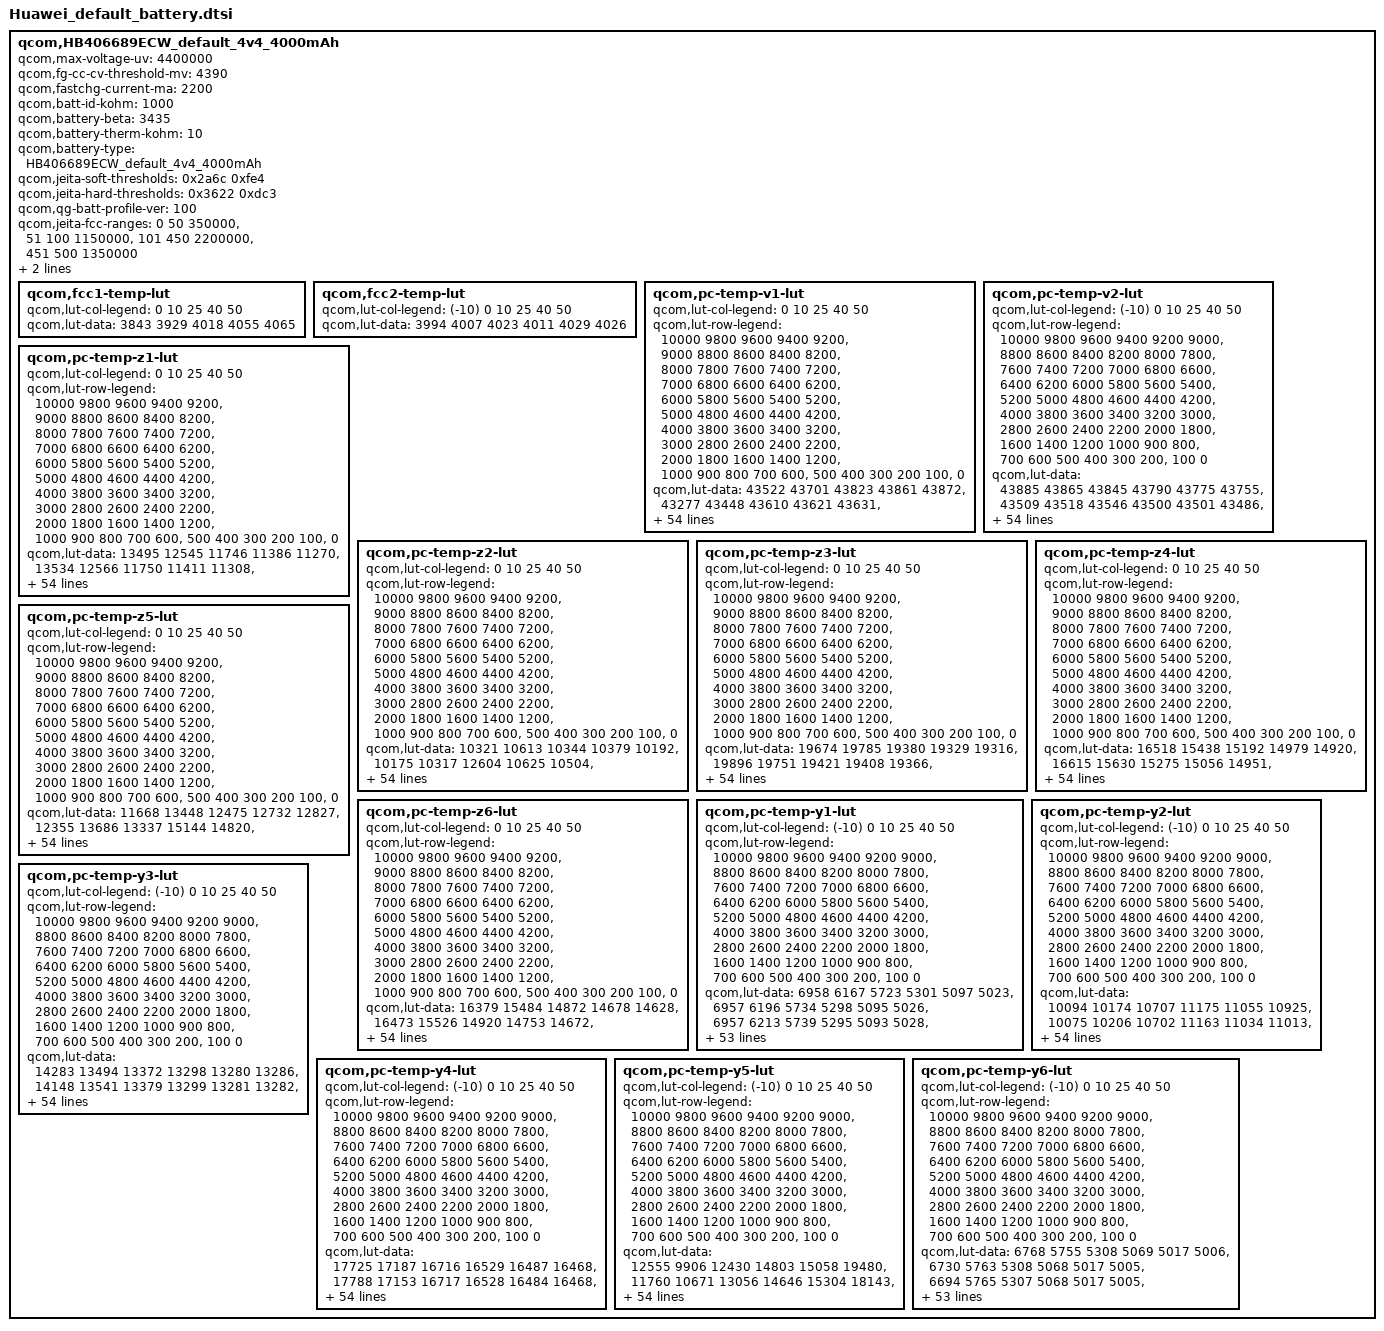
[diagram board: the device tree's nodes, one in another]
/* Copyright (c) 2018, The Linux Foundation. All rights reserved.
 *
 * This program is free software; you can redistribute it and/or modify
 * it under the terms of the GNU General Public License version 2 and
 * only version 2 as published by the Free Software Foundation.
 *
 * This program is distributed in the hope that it will be useful,
 * but WITHOUT ANY WARRANTY; without even the implied warranty of
 * MERCHANTABILITY or FITNESS FOR A PARTICULAR PURPOSE.  See the
 * GNU General Public License for more details.
 */

qcom,HB406689ECW_default_4v4_4000mAh {
	/* 3460679_Huawei_Bangkok_desay_4000mAh_averaged_MasterSlave_May29th2018 */
	qcom,max-voltage-uv = <4400000>;
	qcom,fg-cc-cv-threshold-mv = <4390>;
	qcom,fastchg-current-ma = <2200>;
	qcom,batt-id-kohm = <1000>;
	qcom,battery-beta = <3435>;
	qcom,battery-therm-kohm = <10>;
	qcom,battery-type = "HB406689ECW_default_4v4_4000mAh";
	qcom,jeita-soft-thresholds = <0x2a6c 0xfe4>;
	qcom,jeita-hard-thresholds = <0x3622 0xdc3>;
	qcom,qg-batt-profile-ver = <100>;

	qcom,jeita-fcc-ranges = <0   50  350000>,
				<51  100  1150000>,
				<101  450  2200000>,
				<451  500  1350000>;
	qcom,jeita-fv-ranges = <0   450  4400000>,
				<451 500  4100000>;

	qcom,fcc1-temp-lut {
		qcom,lut-col-legend = <0 10 25 40 50>;
		qcom,lut-data = <3843 3929 4018 4055 4065>;
	};

	qcom,fcc2-temp-lut {
		qcom,lut-col-legend = <(-10) 0 10 25 40 50>;
		qcom,lut-data = <3994 4007 4023 4011 4029 4026>;
	};

	qcom,pc-temp-v1-lut {
		qcom,lut-col-legend = <0 10 25 40 50>;
		qcom,lut-row-legend = <10000 9800 9600 9400 9200>,
			<9000 8800 8600 8400 8200>,
			<8000 7800 7600 7400 7200>,
			<7000 6800 6600 6400 6200>,
			<6000 5800 5600 5400 5200>,
			<5000 4800 4600 4400 4200>,
			<4000 3800 3600 3400 3200>,
			<3000 2800 2600 2400 2200>,
			<2000 1800 1600 1400 1200>,
			<1000 900 800 700 600>,
			<500 400 300 200 100>,
			<0>;
		qcom,lut-data = <43522 43701 43823 43861 43872>,
			<43277 43448 43610 43621 43631>,
			<43036 43204 43364 43394 43405>,
			<42798 42966 43119 43168 43181>,
			<42564 42734 42884 42935 42951>,
			<42334 42501 42651 42698 42719>,
			<42110 42271 42418 42465 42486>,
			<41893 42047 42185 42232 42254>,
			<41682 41827 41956 42002 42024>,
			<41480 41611 41729 41775 41794>,
			<41289 41403 41506 41550 41566>,
			<41095 41201 41292 41330 41344>,
			<40889 41002 41085 41112 41128>,
			<40679 40807 40880 40901 40919>,
			<40463 40612 40675 40697 40713>,
			<40233 40404 40474 40500 40514>,
			<40024 40182 40277 40307 40323>,
			<39861 39990 40088 40120 40142>,
			<39724 39846 39920 39943 39968>,
			<39597 39717 39782 39792 39810>,
			<39481 39577 39634 39641 39653>,
			<39368 39432 39432 39438 39455>,
			<39240 39269 39195 39169 39195>,
			<39099 39039 38987 38951 38977>,
			<38960 38793 38797 38811 38834>,
			<38826 38652 38647 38697 38718>,
			<38699 38569 38560 38597 38612>,
			<38602 38505 38496 38509 38515>,
			<38526 38450 38431 38424 38423>,
			<38462 38404 38365 38336 38329>,
			<38410 38358 38302 38255 38242>,
			<38364 38311 38241 38187 38170>,
			<38324 38267 38184 38128 38108>,
			<38287 38226 38131 38071 38048>,
			<38253 38189 38085 38018 37989>,
			<38217 38150 38041 37966 37931>,
			<38182 38115 38000 37917 37873>,
			<38140 38075 37959 37871 37815>,
			<38077 38010 37900 37808 37743>,
			<37995 37913 37810 37719 37652>,
			<37895 37804 37703 37613 37546>,
			<37763 37679 37583 37493 37428>,
			<37616 37538 37447 37354 37292>,
			<37453 37375 37286 37196 37131>,
			<37324 37237 37147 37061 36999>,
			<37231 37156 37064 36981 36923>,
			<37207 37131 37040 36961 36904>,
			<37185 37111 37026 36949 36889>,
			<37159 37094 37007 36927 36866>,
			<37093 37030 36944 36838 36760>,
			<36816 36734 36664 36519 36429>,
			<36349 36270 36215 36058 35964>,
			<35748 35672 35627 35454 35359>,
			<34926 34842 34820 34622 34525>,
			<33595 33521 33557 33301 33198>,
			<30000 30000 30000 30000 30000>;
	};

	qcom,pc-temp-v2-lut {
		qcom,lut-col-legend = <(-10) 0 10 25 40 50>;
		qcom,lut-row-legend = <10000 9800 9600 9400 9200 9000>,
			<8800 8600 8400 8200 8000 7800>,
			<7600 7400 7200 7000 6800 6600>,
			<6400 6200 6000 5800 5600 5400>,
			<5200 5000 4800 4600 4400 4200>,
			<4000 3800 3600 3400 3200 3000>,
			<2800 2600 2400 2200 2000 1800>,
			<1600 1400 1200 1000 900 800>,
			<700 600 500 400 300 200>,
			<100 0>;
		qcom,lut-data = <43885 43865 43845 43790 43775 43755>,
			<43509 43518 43546 43500 43501 43486>,
			<43165 43201 43265 43228 43238 43228>,
			<42856 42919 43003 42973 42990 42982>,
			<42573 42671 42761 42737 42756 42748>,
			<42326 42429 42523 42506 42524 42516>,
			<42128 42183 42285 42273 42291 42284>,
			<41946 41940 42051 42042 42059 42054>,
			<41713 41705 41823 41815 41831 41827>,
			<41406 41472 41600 41590 41605 41601>,
			<41177 41258 41383 41369 41383 41379>,
			<41086 41078 41173 41154 41163 41161>,
			<41016 40906 40968 40943 40947 40947>,
			<40824 40711 40767 40739 40744 40741>,
			<40321 40492 40569 40540 40548 40541>,
			<39874 40256 40369 40344 40355 40348>,
			<39653 39978 40165 40140 40156 40161>,
			<39482 39695 39959 39944 39964 39981>,
			<39307 39488 39748 39780 39796 39812>,
			<39132 39329 39531 39645 39649 39655>,
			<38963 39172 39323 39488 39480 39481>,
			<38792 38994 39121 39253 39254 39258>,
			<38629 38819 38932 38999 39022 39031>,
			<38498 38669 38771 38811 38840 38849>,
			<38387 38540 38629 38660 38683 38692>,
			<38295 38415 38503 38532 38550 38558>,
			<38220 38276 38391 38421 38437 38445>,
			<38156 38148 38290 38322 38339 38345>,
			<38095 38069 38197 38231 38248 38251>,
			<38035 38014 38110 38147 38165 38164>,
			<37979 37967 38029 38072 38090 38087>,
			<37923 37921 37949 38001 38021 38017>,
			<37869 37879 37879 37937 37956 37951>,
			<37813 37836 37828 37875 37888 37884>,
			<37759 37795 37789 37818 37821 37818>,
			<37702 37750 37750 37761 37745 37737>,
			<37637 37700 37712 37701 37653 37625>,
			<37569 37644 37671 37638 37558 37507>,
			<37499 37583 37618 37568 37474 37415>,
			<37428 37516 37550 37490 37395 37334>,
			<37356 37437 37467 37403 37307 37245>,
			<37283 37334 37357 37301 37208 37146>,
			<37209 37215 37229 37181 37089 37029>,
			<37137 37079 37078 37032 36943 36884>,
			<37053 36963 36948 36918 36846 36788>,
			<36955 36873 36887 36876 36816 36764>,
			<36900 36841 36866 36861 36802 36747>,
			<36837 36806 36844 36842 36780 36728>,
			<36764 36752 36804 36805 36733 36679>,
			<36634 36646 36684 36689 36560 36492>,
			<36391 36373 36355 36361 36160 36083>,
			<35975 35891 35825 35848 35613 35540>,
			<35369 35221 35119 35181 34899 34822>,
			<34492 34264 34117 34271 33895 33844>,
			<33004 32661 32620 32827 32381 32322>,
			<28729 27708 27041 28388 27084 27118>;
	};

	qcom,pc-temp-z1-lut {
		qcom,lut-col-legend = <0 10 25 40 50>;
		qcom,lut-row-legend = <10000 9800 9600 9400 9200>,
			<9000 8800 8600 8400 8200>,
			<8000 7800 7600 7400 7200>,
			<7000 6800 6600 6400 6200>,
			<6000 5800 5600 5400 5200>,
			<5000 4800 4600 4400 4200>,
			<4000 3800 3600 3400 3200>,
			<3000 2800 2600 2400 2200>,
			<2000 1800 1600 1400 1200>,
			<1000 900 800 700 600>,
			<500 400 300 200 100>,
			<0>;
		qcom,lut-data = <13495 12545 11746 11386 11270>,
			<13534 12566 11750 11411 11308>,
			<13548 12567 11761 11415 11311>,
			<13557 12558 11761 11415 11311>,
			<13564 12550 11754 11413 11311>,
			<13570 12549 11745 11409 11310>,
			<13577 12546 11736 11406 11309>,
			<13588 12545 11726 11404 11309>,
			<13595 12544 11720 11401 11308>,
			<13588 12541 11717 11400 11307>,
			<13560 12537 11714 11399 11304>,
			<13538 12531 11714 11398 11303>,
			<13527 12523 11713 11398 11303>,
			<13515 12493 11712 11397 11304>,
			<13506 12459 11708 11395 11303>,
			<13500 12454 11704 11393 11302>,
			<13493 12454 11702 11393 11302>,
			<13479 12454 11699 11394 11302>,
			<13459 12446 11699 11394 11303>,
			<13436 12436 11703 11396 11305>,
			<13408 12436 11708 11398 11306>,
			<13384 12450 11712 11399 11308>,
			<13376 12462 11716 11401 11309>,
			<13381 12469 11720 11403 11311>,
			<13385 12476 11724 11405 11312>,
			<13388 12478 11729 11408 11315>,
			<13392 12479 11733 11411 11317>,
			<13389 12480 11736 11415 11321>,
			<13371 12478 11741 11419 11324>,
			<13355 12476 11747 11424 11327>,
			<13358 12476 11753 11430 11331>,
			<13368 12482 11759 11435 11334>,
			<13372 12489 11763 11440 11338>,
			<13380 12492 11767 11443 11341>,
			<13393 12495 11770 11445 11345>,
			<13407 12498 11773 11447 11347>,
			<13430 12502 11780 11449 11350>,
			<13442 12508 11788 11452 11352>,
			<13434 12512 11795 11455 11355>,
			<13421 12517 11800 11460 11358>,
			<13418 12523 11805 11465 11361>,
			<13423 12541 11811 11470 11363>,
			<13426 12555 11818 11474 11365>,
			<13427 12567 11824 11477 11368>,
			<13441 12562 11832 11482 11372>,
			<13401 12555 11839 11486 11375>,
			<13400 12546 11837 11487 11375>,
			<13408 12521 11841 11487 11376>,
			<13404 12544 11847 11489 11377>,
			<13420 12543 11842 11493 11382>,
			<13414 12563 11853 11499 11385>,
			<13430 12573 11867 11505 11390>,
			<13442 12593 11878 11514 11398>,
			<13456 12600 11897 11527 11409>,
			<13456 12600 11897 11527 11409>,
			<13456 12600 11897 11527 11409>;
	};

	qcom,pc-temp-z2-lut {
		qcom,lut-col-legend = <0 10 25 40 50>;
		qcom,lut-row-legend = <10000 9800 9600 9400 9200>,
			<9000 8800 8600 8400 8200>,
			<8000 7800 7600 7400 7200>,
			<7000 6800 6600 6400 6200>,
			<6000 5800 5600 5400 5200>,
			<5000 4800 4600 4400 4200>,
			<4000 3800 3600 3400 3200>,
			<3000 2800 2600 2400 2200>,
			<2000 1800 1600 1400 1200>,
			<1000 900 800 700 600>,
			<500 400 300 200 100>,
			<0>;
		qcom,lut-data = <10321 10613 10344 10379 10192>,
			<10175 10317 12604 10625 10504>,
			<10148 10212 11188 11027 10977>,
			<10133 10197 10443 11277 11321>,
			<10120 10188 10422 11061 11296>,
			<10110 10176 10403 10642 11169>,
			<10106 10165 10386 10557 11007>,
			<10111 10158 10370 10722 10731>,
			<10117 10155 10366 10848 10540>,
			<10119 10156 10384 10860 10537>,
			<10128 10160 10408 10872 10542>,
			<10135 10170 10422 10892 10576>,
			<10136 10184 10434 10931 10766>,
			<10136 10210 10463 10953 10920>,
			<10130 10240 10588 10938 10965>,
			<10082 10263 10682 10898 11000>,
			<10040 10284 10718 10812 10944>,
			<10057 10304 10807 10599 10581>,
			<10103 10326 10810 10487 10346>,
			<10121 10343 10635 10502 10357>,
			<10082 10345 10488 10537 10389>,
			<10037 10336 10515 10594 10474>,
			<10053 10328 10583 10712 10719>,
			<10134 10318 10597 10765 10859>,
			<10189 10309 10543 10600 10677>,
			<10201 10308 10496 10397 10420>,
			<10211 10317 10493 10408 10402>,
			<10221 10327 10494 10529 10489>,
			<10228 10333 10505 10625 10553>,
			<10237 10339 10567 10696 10585>,
			<10249 10347 10616 10744 10605>,
			<10263 10357 10592 10705 10578>,
			<10278 10367 10544 10581 10482>,
			<10295 10372 10527 10533 10441>,
			<10312 10375 10523 10561 10482>,
			<10332 10379 10521 10605 10544>,
			<10355 10386 10529 10650 10603>,
			<10379 10394 10549 10703 10671>,
			<10405 10406 10573 10741 10705>,
			<10434 10425 10610 10770 10705>,
			<10467 10445 10642 10789 10697>,
			<10508 10464 10656 10798 10708>,
			<10570 10495 10669 10802 10728>,
			<10686 10570 10695 10784 10721>,
			<10898 10889 10825 10799 10670>,
			<11114 11109 10913 10813 10594>,
			<10449 11192 10894 10712 10552>,
			<10384 11229 10922 10683 10571>,
			<10369 11234 10893 10697 10605>,
			<10369 11257 10999 10878 10656>,
			<10399 11426 11258 10831 10488>,
			<10232 11396 11217 10758 10378>,
			<10091 10856 11210 10661 10346>,
			<9949 10726 11167 10611 10274>,
			<9949 10726 11167 10611 10274>,
			<9949 10726 11167 10611 10274>;
	};

	qcom,pc-temp-z3-lut {
		qcom,lut-col-legend = <0 10 25 40 50>;
		qcom,lut-row-legend = <10000 9800 9600 9400 9200>,
			<9000 8800 8600 8400 8200>,
			<8000 7800 7600 7400 7200>,
			<7000 6800 6600 6400 6200>,
			<6000 5800 5600 5400 5200>,
			<5000 4800 4600 4400 4200>,
			<4000 3800 3600 3400 3200>,
			<3000 2800 2600 2400 2200>,
			<2000 1800 1600 1400 1200>,
			<1000 900 800 700 600>,
			<500 400 300 200 100>,
			<0>;
		qcom,lut-data = <19674 19785 19380 19329 19316>,
			<19896 19751 19421 19408 19366>,
			<19982 19756 19514 19439 19394>,
			<20030 19782 19557 19455 19416>,
			<20058 19800 19561 19460 19432>,
			<20078 19801 19563 19463 19444>,
			<20084 19801 19563 19468 19446>,
			<20072 19800 19563 19482 19431>,
			<20057 19792 19561 19491 19415>,
			<20053 19781 19551 19480 19411>,
			<20039 19779 19540 19460 19409>,
			<20033 19778 19528 19452 19408>,
			<20040 19775 19516 19449 19407>,
			<20050 19756 19512 19446 19405>,
			<20075 19731 19523 19440 19403>,
			<20169 19722 19532 19430 19401>,
			<20246 19717 19533 19419 19394>,
			<20233 19713 19534 19404 19372>,
			<20182 19698 19528 19392 19355>,
			<20129 19681 19499 19385 19351>,
			<19965 19680 19477 19380 19348>,
			<19800 19695 19489 19386 19352>,
			<19832 19714 19518 19411 19373>,
			<20018 19741 19526 19425 19385>,
			<20126 19770 19517 19406 19366>,
			<20121 19775 19505 19379 19338>,
			<20115 19768 19489 19369 19335>,
			<20107 19758 19473 19362 19339>,
			<20089 19747 19469 19361 19345>,
			<20068 19734 19474 19395 19375>,
			<20048 19725 19480 19433 19410>,
			<20026 19720 19492 19434 19409>,
			<20002 19716 19509 19427 19395>,
			<19975 19712 19513 19421 19384>,
			<19947 19708 19508 19415 19378>,
			<19924 19704 19503 19409 19374>,
			<19903 19699 19498 19405 19372>,
			<19884 19694 19493 19401 19370>,
			<19866 19690 19488 19396 19368>,
			<19848 19686 19481 19390 19367>,
			<19824 19679 19476 19385 19366>,
			<19787 19667 19472 19386 19365>,
			<19741 19648 19468 19388 19364>,
			<19678 19615 19458 19382 19365>,
			<19435 19529 19433 19371 19359>,
			<19404 19464 19409 19360 19343>,
			<19346 19444 19411 19353 19335>,
			<19339 19431 19396 19341 19334>,
			<19337 19367 19402 19338 19326>,
			<19333 19372 19384 19329 19332>,
			<19340 19412 19349 19331 19341>,
			<19342 19399 19334 19329 19349>,
			<19345 19332 19334 19331 19348>,
			<19352 19331 19333 19335 19355>,
			<19352 19331 19333 19335 19355>,
			<19352 19331 19333 19335 19355>;
	};

	qcom,pc-temp-z4-lut {
		qcom,lut-col-legend = <0 10 25 40 50>;
		qcom,lut-row-legend = <10000 9800 9600 9400 9200>,
			<9000 8800 8600 8400 8200>,
			<8000 7800 7600 7400 7200>,
			<7000 6800 6600 6400 6200>,
			<6000 5800 5600 5400 5200>,
			<5000 4800 4600 4400 4200>,
			<4000 3800 3600 3400 3200>,
			<3000 2800 2600 2400 2200>,
			<2000 1800 1600 1400 1200>,
			<1000 900 800 700 600>,
			<500 400 300 200 100>,
			<0>;
		qcom,lut-data = <16518 15438 15192 14979 14920>,
			<16615 15630 15275 15056 14951>,
			<16383 15661 15213 15009 14925>,
			<16107 15526 15149 14952 14883>,
			<15930 15358 15086 14922 14848>,
			<15781 15261 15026 14896 14812>,
			<15675 15184 14978 14863 14794>,
			<15597 15125 14936 14811 14783>,
			<15533 15079 14898 14773 14775>,
			<15480 15040 14859 14763 14767>,
			<15428 15001 14829 14757 14756>,
			<15381 14962 14816 14748 14746>,
			<15340 14931 14807 14735 14729>,
			<15301 14905 14794 14724 14714>,
			<15247 14886 14763 14716 14704>,
			<15152 14885 14740 14710 14692>,
			<15082 14892 14725 14707 14689>,
			<15076 14895 14699 14713 14702>,
			<15075 14883 14691 14714 14710>,
			<15080 14861 14700 14709 14704>,
			<15212 14839 14715 14703 14697>,
			<15351 14810 14737 14715 14705>,
			<15286 14794 14771 14773 14758>,
			<15032 14834 14811 14825 14809>,
			<14884 14902 14870 14859 14842>,
			<14888 14918 14910 14883 14866>,
			<14896 14914 14908 14883 14865>,
			<14899 14909 14901 14873 14846>,
			<14901 14899 14890 14858 14820>,
			<14903 14885 14866 14806 14769>,
			<14901 14871 14837 14750 14717>,
			<14896 14855 14804 14729 14705>,
			<14894 14840 14769 14717 14700>,
			<14894 14827 14752 14712 14699>,
			<14894 14815 14743 14711 14699>,
			<14893 14805 14739 14711 14699>,
			<14892 14796 14738 14712 14701>,
			<14891 14790 14738 14716 14707>,
			<14886 14790 14741 14722 14713>,
			<14880 14791 14757 14736 14721>,
			<14882 14791 14769 14747 14727>,
			<14898 14788 14763 14741 14722>,
			<14906 14786 14755 14732 14715>,
			<14912 14786 14755 14737 14716>,
			<14971 14769 14740 14728 14710>,
			<14964 14776 14715 14703 14694>,
			<15025 14789 14701 14695 14688>,
			<15028 14795 14698 14686 14665>,
			<15022 14863 14682 14673 14655>,
			<15014 14853 14707 14694 14663>,
			<15020 14820 14773 14725 14686>,
			<15031 14843 14797 14734 14683>,
			<15033 14926 14802 14735 14685>,
			<15042 14931 14805 14734 14681>,
			<15042 14931 14805 14734 14681>,
			<15042 14931 14805 14734 14681>;
	};

	qcom,pc-temp-z5-lut {
		qcom,lut-col-legend = <0 10 25 40 50>;
		qcom,lut-row-legend = <10000 9800 9600 9400 9200>,
			<9000 8800 8600 8400 8200>,
			<8000 7800 7600 7400 7200>,
			<7000 6800 6600 6400 6200>,
			<6000 5800 5600 5400 5200>,
			<5000 4800 4600 4400 4200>,
			<4000 3800 3600 3400 3200>,
			<3000 2800 2600 2400 2200>,
			<2000 1800 1600 1400 1200>,
			<1000 900 800 700 600>,
			<500 400 300 200 100>,
			<0>;
		qcom,lut-data = <11668 13448 12475 12732 12827>,
			<12355 13686 13337 15144 14820>,
			<12721 13974 14957 15978 15900>,
			<12991 14364 15811 16490 16904>,
			<13248 14748 15968 16843 18033>,
			<13471 15044 16104 17122 19189>,
			<13569 15320 16387 17851 19506>,
			<13563 15522 16805 20101 19021>,
			<13540 15694 17312 21611 18589>,
			<13560 15903 18152 21500 18721>,
			<13631 16316 18805 21231 19172>,
			<13748 17118 18865 21377 19721>,
			<13887 17648 18874 22726 20918>,
			<14078 17848 19264 23638 22272>,
			<14727 17988 22131 23546 23949>,
			<17516 18115 24464 23309 25648>,
			<19814 18244 25343 22634 25259>,
			<19600 18316 27250 20797 20971>,
			<18682 18241 27476 20055 18190>,
			<17735 18169 25523 20552 18468>,
			<16497 18796 23989 21401 19281>,
			<15915 21902 31103 25024 21645>,
			<18125 26288 46456 35915 29252>,
			<24328 34430 50268 41507 33746>,
			<29948 44043 41943 33168 27410>,
			<34073 45507 32490 21713 18116>,
			<37461 39936 26808 18119 15850>,
			<37988 33913 22307 16340 15152>,
			<36271 30276 20783 15900 15020>,
			<34149 27365 20270 18871 19213>,
			<32416 26288 20059 22816 24274>,
			<30340 25930 21815 24699 24761>,
			<28467 25816 25663 26099 24611>,
			<26479 26037 28350 27587 24626>,
			<24635 26461 30494 29712 26408>,
			<23473 26744 31615 31204 28256>,
			<22536 26903 31509 30936 28210>,
			<21984 27133 31144 29770 27626>,
			<21945 27767 30327 28068 26725>,
			<22068 28872 27648 24384 24280>,
			<21755 29296 25286 21584 21954>,
			<20137 28032 24479 21443 21188>,
			<19100 26156 23820 21414 20746>,
			<18197 23984 22255 19805 20487>,
			<14684 22687 22196 19354 19805>,
			<14206 19162 21838 19372 18432>,
			<12866 17306 22551 18789 17403>,
			<12708 16606 20061 17583 18897>,
			<12700 14133 21461 18210 19633>,
			<12777 14542 18318 16095 18814>,
			<12932 15632 14408 14352 16320>,
			<12773 14794 13498 13842 16625>,
			<12696 12781 13272 13698 15976>,
			<12590 12642 13084 13610 16263>,
			<12590 12642 13084 13610 16263>,
			<12590 12642 13084 13610 16263>;
	};

	qcom,pc-temp-z6-lut {
		qcom,lut-col-legend = <0 10 25 40 50>;
		qcom,lut-row-legend = <10000 9800 9600 9400 9200>,
			<9000 8800 8600 8400 8200>,
			<8000 7800 7600 7400 7200>,
			<7000 6800 6600 6400 6200>,
			<6000 5800 5600 5400 5200>,
			<5000 4800 4600 4400 4200>,
			<4000 3800 3600 3400 3200>,
			<3000 2800 2600 2400 2200>,
			<2000 1800 1600 1400 1200>,
			<1000 900 800 700 600>,
			<500 400 300 200 100>,
			<0>;
		qcom,lut-data = <16379 15484 14872 14678 14628>,
			<16473 15526 14920 14753 14672>,
			<16378 15529 14939 14749 14674>,
			<16259 15468 14946 14741 14673>,
			<16176 15390 14922 14733 14670>,
			<16101 15339 14889 14721 14662>,
			<16039 15297 14866 14708 14652>,
			<15988 15260 14847 14696 14640>,
			<15944 15229 14827 14683 14628>,
			<15904 15202 14804 14670 14621>,
			<15868 15179 14784 14658 14615>,
			<15835 15159 14771 14649 14609>,
			<15803 15138 14761 14642 14602>,
			<15777 15107 14753 14635 14595>,
			<15768 15080 14746 14627 14589>,
			<15767 15074 14740 14619 14582>,
			<15765 15072 14732 14612 14576>,
			<15751 15069 14724 14605 14569>,
			<15719 15055 14715 14599 14563>,
			<15687 15037 14705 14593 14558>,
			<15655 15032 14699 14588 14554>,
			<15626 15031 14711 14597 14560>,
			<15607 15030 14743 14639 14598>,
			<15591 15059 14767 14662 14621>,
			<15582 15107 14787 14663 14622>,
			<15580 15118 14799 14664 14622>,
			<15580 15115 14795 14662 14621>,
			<15577 15110 14784 14655 14615>,
			<15569 15101 14775 14648 14609>,
			<15559 15089 14768 14644 14605>,
			<15549 15079 14761 14640 14600>,
			<15538 15071 14755 14634 14594>,
			<15526 15064 14749 14625 14585>,
			<15513 15058 14744 14620 14580>,
			<15501 15052 14739 14616 14576>,
			<15491 15048 14735 14613 14575>,
			<15484 15044 14733 14612 14575>,
			<15477 15042 14731 14612 14575>,
			<15473 15043 14732 14612 14577>,
			<15469 15044 14737 14615 14579>,
			<15462 15045 14740 14618 14582>,
			<15452 15041 14738 14617 14580>,
			<15437 15035 14733 14614 14577>,
			<15414 15024 14730 14613 14578>,
			<15325 14979 14714 14605 14573>,
			<15305 14952 14692 14589 14558>,
			<15299 14949 14687 14582 14551>,
			<15297 14945 14679 14571 14541>,
			<15295 14941 14675 14564 14531>,
			<15297 14946 14678 14569 14538>,
			<15311 14957 14691 14586 14555>,
			<15324 14964 14696 14590 14560>,
			<15337 14973 14701 14594 14563>,
			<15362 14986 14707 14598 14567>,
			<15362 14986 14707 14598 14567>,
			<15362 14986 14707 14598 14567>;
	};

	qcom,pc-temp-y1-lut {
		qcom,lut-col-legend = <(-10) 0 10 25 40 50>;
		qcom,lut-row-legend = <10000 9800 9600 9400 9200 9000>,
			<8800 8600 8400 8200 8000 7800>,
			<7600 7400 7200 7000 6800 6600>,
			<6400 6200 6000 5800 5600 5400>,
			<5200 5000 4800 4600 4400 4200>,
			<4000 3800 3600 3400 3200 3000>,
			<2800 2600 2400 2200 2000 1800>,
			<1600 1400 1200 1000 900 800>,
			<700 600 500 400 300 200>,
			<100 0>;
		qcom,lut-data = <6958 6167 5723 5301 5097 5023>,
			<6957 6196 5734 5298 5095 5026>,
			<6957 6213 5739 5295 5093 5028>,
			<6957 6221 5741 5292 5091 5028>,
			<6958 6222 5741 5288 5089 5029>,
			<6959 6220 5740 5285 5088 5029>,
			<6961 6207 5735 5281 5087 5028>,
			<6964 6189 5728 5277 5086 5026>,
			<6966 6187 5725 5275 5084 5025>,
			<6974 6195 5721 5274 5083 5024>,
			<6979 6201 5717 5273 5082 5023>,
			<6974 6205 5714 5270 5081 5023>,
			<6967 6207 5713 5267 5080 5022>,
			<6964 6208 5712 5266 5079 5022>,
			<6954 6210 5711 5267 5077 5021>,
			<6947 6212 5709 5267 5076 5020>,
			<6947 6215 5710 5269 5077 5022>,
			<6947 6220 5711 5271 5078 5023>,
			<6947 6219 5711 5272 5078 5023>,
			<6945 6210 5709 5272 5078 5023>,
			<6944 6205 5709 5272 5078 5023>,
			<6944 6216 5707 5274 5079 5024>,
			<6942 6234 5706 5277 5079 5025>,
			<6938 6237 5708 5279 5080 5026>,
			<6925 6234 5712 5281 5082 5027>,
			<6914 6231 5717 5284 5084 5027>,
			<6915 6229 5725 5288 5087 5029>,
			<6917 6228 5733 5292 5091 5030>,
			<6915 6223 5738 5296 5093 5032>,
			<6906 6213 5741 5300 5095 5035>,
			<6898 6207 5743 5305 5096 5037>,
			<6902 6212 5740 5310 5099 5040>,
			<6913 6219 5735 5315 5103 5043>,
			<6915 6218 5736 5320 5107 5046>,
			<6903 6209 5739 5324 5112 5050>,
			<6894 6202 5741 5328 5115 5052>,
			<6896 6199 5744 5332 5117 5052>,
			<6901 6197 5747 5336 5119 5052>,
			<6902 6197 5749 5339 5121 5054>,
			<6896 6201 5755 5343 5123 5056>,
			<6890 6204 5760 5347 5125 5057>,
			<6896 6200 5767 5350 5127 5058>,
			<6902 6194 5771 5354 5129 5059>,
			<6928 6185 5788 5360 5133 5063>,
			<6920 6188 5766 5363 5137 5067>,
			<6929 6236 5782 5372 5138 5066>,
			<6939 6238 5801 5367 5140 5068>,
			<6916 6211 5792 5373 5139 5067>,
			<6945 6220 5767 5372 5137 5067>,
			<6973 6234 5777 5380 5138 5069>,
			<6928 6227 5796 5383 5143 5070>,
			<6963 6218 5781 5389 5148 5074>,
			<6917 6238 5802 5405 5156 5081>,
			<6921 6260 5795 5415 5163 5089>,
			<6921 6260 5795 5415 5163 5089>,
			<6921 6260 5795 5415 5163 5089>;
	};

	qcom,pc-temp-y2-lut {
		qcom,lut-col-legend = <(-10) 0 10 25 40 50>;
		qcom,lut-row-legend = <10000 9800 9600 9400 9200 9000>,
			<8800 8600 8400 8200 8000 7800>,
			<7600 7400 7200 7000 6800 6600>,
			<6400 6200 6000 5800 5600 5400>,
			<5200 5000 4800 4600 4400 4200>,
			<4000 3800 3600 3400 3200 3000>,
			<2800 2600 2400 2200 2000 1800>,
			<1600 1400 1200 1000 900 800>,
			<700 600 500 400 300 200>,
			<100 0>;
		qcom,lut-data = <10094 10174 10707 11175 11055 10925>,
			<10075 10206 10702 11163 11034 11013>,
			<10076 10238 10694 11148 11042 11064>,
			<10091 10265 10685 11132 11064 11086>,
			<10117 10285 10678 11117 11087 11090>,
			<10151 10295 10674 11108 11097 11083>,
			<10195 10292 10674 11101 11102 11041>,
			<10251 10286 10674 11095 11115 10986>,
			<10324 10293 10678 11093 11131 10984>,
			<10432 10324 10693 11092 11151 11017>,
			<10497 10365 10702 11090 11159 11047>,
			<10502 10471 10703 11085 11117 11068>,
			<10501 10600 10704 11079 11063 11082>,
			<10469 10623 10723 11085 11066 11062>,
			<10312 10612 10801 11122 11112 10986>,
			<10211 10607 10857 11164 11160 10948>,
			<10033 10638 10874 11202 11203 11013>,
			<9738 10697 10886 11240 11246 11122>,
			<9671 10758 10902 11268 11295 11212>,
			<9669 10830 10921 11294 11362 11304>,
			<9668 10899 10944 11304 11390 11340>,
			<9667 10979 10979 11264 11351 11320>,
			<9666 11047 11023 11209 11297 11281>,
			<9664 11047 11073 11207 11266 11224>,
			<9663 11002 11133 11243 11241 11137>,
			<9662 10976 11180 11285 11234 11103>,
			<9661 11024 11215 11330 11262 11141>,
			<9661 11094 11239 11374 11304 11199>,
			<9660 11002 11245 11397 11357 11242>,
			<9660 10606 11248 11412 11444 11282>,
			<9660 10371 11252 11427 11498 11333>,
			<9659 10127 11261 11454 11525 11417>,
			<9659 9789 11269 11476 11540 11491>,
			<9659 9704 11257 11477 11545 11518>,
			<9658 9687 11214 11470 11549 11538>,
			<9658 9678 11174 11458 11545 11541>,
			<9658 9674 11145 11429 11470 11469>,
			<9657 9671 11116 11395 11388 11383>,
			<9657 9668 11082 11385 11380 11350>,
			<9657 9666 11046 11388 11396 11330>,
			<9657 9663 11009 11387 11407 11304>,
			<9657 9662 10974 11366 11417 11264>,
			<9656 9660 10923 11334 11399 11256>,
			<9656 9659 10836 11301 11333 11295>,
			<9656 9658 10753 11244 11204 11136>,
			<9656 9658 10713 11240 11260 11041>,
			<9656 9657 10683 11227 11205 10977>,
			<9656 9657 10653 11183 11192 11038>,
			<9656 9656 10626 11160 11145 11048>,
			<9656 9656 10578 11115 11135 11028>,
			<9655 9655 10236 11099 11096 10918>,
			<9655 9654 9979 11029 11045 10870>,
			<9654 9654 9714 10936 10991 10831>,
			<9653 9653 9679 10836 10880 10743>,
			<9653 9653 9679 10836 10880 10743>,
			<9653 9653 9679 10836 10880 10743>;
	};

	qcom,pc-temp-y3-lut {
		qcom,lut-col-legend = <(-10) 0 10 25 40 50>;
		qcom,lut-row-legend = <10000 9800 9600 9400 9200 9000>,
			<8800 8600 8400 8200 8000 7800>,
			<7600 7400 7200 7000 6800 6600>,
			<6400 6200 6000 5800 5600 5400>,
			<5200 5000 4800 4600 4400 4200>,
			<4000 3800 3600 3400 3200 3000>,
			<2800 2600 2400 2200 2000 1800>,
			<1600 1400 1200 1000 900 800>,
			<700 600 500 400 300 200>,
			<100 0>;
		qcom,lut-data = <14283 13494 13372 13298 13280 13286>,
			<14148 13541 13379 13299 13281 13282>,
			<14058 13572 13384 13299 13282 13280>,
			<14003 13591 13388 13300 13283 13279>,
			<13976 13600 13391 13301 13285 13279>,
			<13969 13603 13392 13302 13286 13280>,
			<14003 13590 13391 13303 13287 13281>,
			<14057 13572 13389 13304 13288 13284>,
			<14021 13574 13389 13305 13289 13285>,
			<13767 13601 13390 13304 13289 13286>,
			<13599 13618 13391 13304 13289 13287>,
			<13634 13564 13391 13307 13289 13287>,
			<13691 13484 13392 13312 13289 13288>,
			<13696 13480 13391 13314 13290 13288>,
			<13656 13523 13390 13316 13295 13287>,
			<13618 13550 13390 13316 13298 13287>,
			<13585 13528 13395 13314 13297 13289>,
			<13553 13494 13401 13312 13295 13292>,
			<13545 13477 13400 13313 13295 13293>,
			<13544 13470 13391 13319 13296 13293>,
			<13544 13460 13382 13323 13296 13293>,
			<13545 13435 13372 13319 13293 13289>,
			<13545 13409 13362 13312 13289 13284>,
			<13546 13405 13354 13307 13287 13282>,
			<13547 13407 13347 13303 13286 13280>,
			<13551 13407 13343 13301 13284 13279>,
			<13567 13382 13342 13300 13283 13279>,
			<13593 13347 13342 13299 13283 13279>,
			<13619 13344 13342 13299 13283 13278>,
			<13645 13353 13343 13301 13285 13277>,
			<13673 13363 13342 13303 13286 13277>,
			<13704 13372 13336 13303 13286 13278>,
			<13738 13381 13330 13304 13286 13279>,
			<13774 13393 13331 13304 13287 13281>,
			<13814 13407 13337 13305 13287 13282>,
			<13855 13423 13342 13306 13287 13283>,
			<13894 13437 13346 13306 13286 13281>,
			<13933 13454 13350 13306 13284 13278>,
			<13976 13479 13353 13305 13283 13279>,
			<14026 13517 13356 13303 13283 13280>,
			<14077 13560 13356 13303 13283 13280>,
			<14126 13611 13353 13303 13284 13281>,
			<14176 13670 13352 13303 13284 13281>,
			<14234 13738 13351 13303 13282 13280>,
			<14283 13820 13349 13301 13285 13279>,
			<14177 13777 13348 13305 13288 13286>,
			<14217 13850 13357 13308 13291 13287>,
			<14291 13928 13366 13312 13296 13293>,
			<14368 14012 13379 13322 13302 13296>,
			<14449 14110 13385 13325 13298 13292>,
			<14549 14204 13386 13321 13292 13289>,
			<14675 14343 13405 13322 13295 13292>,
			<14863 14512 13444 13333 13304 13295>,
			<15143 14692 13519 13348 13313 13302>,
			<15143 14692 13519 13348 13313 13302>,
			<15143 14692 13519 13348 13313 13302>;
	};

	qcom,pc-temp-y4-lut {
		qcom,lut-col-legend = <(-10) 0 10 25 40 50>;
		qcom,lut-row-legend = <10000 9800 9600 9400 9200 9000>,
			<8800 8600 8400 8200 8000 7800>,
			<7600 7400 7200 7000 6800 6600>,
			<6400 6200 6000 5800 5600 5400>,
			<5200 5000 4800 4600 4400 4200>,
			<4000 3800 3600 3400 3200 3000>,
			<2800 2600 2400 2200 2000 1800>,
			<1600 1400 1200 1000 900 800>,
			<700 600 500 400 300 200>,
			<100 0>;
		qcom,lut-data = <17725 17187 16716 16529 16487 16468>,
			<17788 17153 16717 16528 16484 16468>,
			<17816 17133 16718 16528 16482 16468>,
			<17816 17122 16720 16528 16481 16469>,
			<17796 17118 16721 16529 16480 16469>,
			<17761 17117 16722 16531 16480 16469>,
			<17612 17129 16723 16533 16482 16469>,
			<17410 17146 16724 16538 16484 16469>,
			<17443 17133 16727 16544 16488 16470>,
			<17829 17057 16733 16556 16495 16473>,
			<18084 17011 16741 16566 16503 16477>,
			<18061 17174 16750 16572 16511 16482>,
			<18005 17414 16762 16577 16521 16488>,
			<17889 17430 16792 16586 16527 16496>,
			<17559 17293 16860 16607 16532 16508>,
			<17335 17161 16894 16629 16538 16518>,
			<17361 17066 16882 16650 16550 16523>,
			<17424 16989 16857 16672 16566 16529>,
			<17412 16961 16821 16694 16588 16542>,
			<17332 16950 16761 16718 16620 16566>,
			<17244 16937 16709 16729 16633 16577>,
			<17158 16918 16669 16663 16596 16556>,
			<17081 16891 16641 16565 16543 16524>,
			<17056 16850 16632 16531 16513 16501>,
			<17047 16783 16627 16515 16488 16481>,
			<17042 16749 16625 16509 16480 16474>,
			<17039 16748 16623 16514 16484 16476>,
			<17038 16749 16621 16521 16490 16479>,
			<17038 16754 16617 16527 16497 16485>,
			<17039 16770 16608 16533 16507 16495>,
			<17041 16781 16604 16541 16517 16506>,
			<17043 16796 16605 16551 16534 16518>,
			<17046 16817 16607 16561 16546 16528>,
			<17047 16833 16610 16566 16547 16533>,
			<17048 16846 16617 16569 16547 16537>,
			<17049 16858 16626 16570 16544 16536>,
			<17053 16873 16641 16563 16520 16512>,
			<17058 16887 16656 16552 16498 16486>,
			<17061 16894 16665 16545 16496 16481>,
			<17066 16901 16671 16540 16495 16479>,
			<17073 16903 16674 16538 16496 16478>,
			<17089 16894 16675 16542 16498 16480>,
			<17114 16880 16675 16545 16498 16480>,
			<17140 16868 16668 16539 16493 16471>,
			<17153 16862 16665 16535 16480 16468>,
			<17060 16846 16660 16534 16493 16472>,
			<17062 16858 16674 16550 16506 16493>,
			<17086 16887 16702 16573 16526 16516>,
			<17107 16932 16737 16594 16550 16540>,
			<17116 16965 16759 16601 16529 16508>,
			<17096 16954 16761 16561 16496 16473>,
			<17068 16926 16761 16556 16495 16476>,
			<17063 16931 16810 16570 16507 16488>,
			<17108 16964 16868 16627 16577 16569>,
			<17108 16964 16868 16627 16577 16569>,
			<17108 16964 16868 16627 16577 16569>;
	};

	qcom,pc-temp-y5-lut {
		qcom,lut-col-legend = <(-10) 0 10 25 40 50>;
		qcom,lut-row-legend = <10000 9800 9600 9400 9200 9000>,
			<8800 8600 8400 8200 8000 7800>,
			<7600 7400 7200 7000 6800 6600>,
			<6400 6200 6000 5800 5600 5400>,
			<5200 5000 4800 4600 4400 4200>,
			<4000 3800 3600 3400 3200 3000>,
			<2800 2600 2400 2200 2000 1800>,
			<1600 1400 1200 1000 900 800>,
			<700 600 500 400 300 200>,
			<100 0>;
		qcom,lut-data = <12555 9906 12430 14803 15058 19480>,
			<11760 10671 13056 14646 15304 18143>,
			<11399 11518 13566 14488 15453 17077>,
			<11394 12301 13946 14337 15529 16300>,
			<11670 12876 14182 14201 15557 15827>,
			<12154 13097 14261 14088 15560 15677>,
			<14355 12945 14110 13985 15462 16049>,
			<17331 12717 13882 13859 15248 16541>,
			<17229 12821 13827 13634 14977 16496>,
			<13554 13541 13783 13207 14565 16204>,
			<11121 13986 13712 12977 14145 15859>,
			<13072 13259 13510 13147 13678 15482>,
			<16180 12176 13287 13398 13303 15045>,
			<16538 12777 13301 13383 13336 14505>,
			<15121 16579 13572 13069 13655 13815>,
			<14191 18897 14043 12840 13838 13515>,
			<13477 17305 16300 12834 13610 13738>,
			<12313 14995 18921 12933 13293 14021>,
			<12140 14783 19178 13506 13270 14027>,
			<12402 15617 18805 15448 13411 13920>,
			<12572 16117 18344 17176 13728 13891>,
			<12489 15817 17626 18308 15496 14992>,
			<12311 15374 16764 19091 17384 16436>,
			<12096 15815 16071 18878 17577 16910>,
			<11682 18107 15397 17564 17446 17177>,
			<11424 19429 15065 16525 17206 17255>,
			<11427 16739 15222 16022 16359 16798>,
			<11433 12908 15597 15708 15538 16059>,
			<11433 12126 16150 15798 15574 15378>,
			<11428 12124 17114 16393 15894 14657>,
			<11421 12173 17443 16962 16095 14409>,
			<11448 12146 16210 17344 16243 14655>,
			<11495 12112 14869 17707 16458 15116>,
			<11519 12169 14928 18101 16864 15919>,
			<11634 12290 15455 18611 17504 17171>,
			<11720 12341 15838 18932 17857 17627>,
			<11673 12294 16091 18928 17698 17313>,
			<11589 12248 16296 18715 17352 16911>,
			<11559 12310 16415 18162 16735 16739>,
			<11531 12488 16444 17025 15724 16689>,
			<11514 12594 16239 16182 15397 16708>,
			<11480 12626 15417 15753 15375 16354>,
			<11442 12604 14876 15397 15273 16203>,
			<11597 12223 14486 15197 14935 16548>,
			<11734 12146 13763 14682 15669 15036>,
			<11910 11976 13628 14913 14717 16275>,
			<11960 12220 13858 14505 14700 15193>,
			<11960 12302 13990 14314 15058 16099>,
			<12231 12293 14242 15046 15865 16141>,
			<12326 12589 14313 15375 15228 15959>,
			<12363 12442 13550 15541 14914 16822>,
			<12085 12350 13238 15853 15814 17582>,
			<11973 12218 12608 17237 19224 18937>,
			<11770 12059 12752 19622 21735 21886>,
			<11770 12059 12752 19622 21735 21886>,
			<11770 12059 12752 19622 21735 21886>;
	};

	qcom,pc-temp-y6-lut {
		qcom,lut-col-legend = <(-10) 0 10 25 40 50>;
		qcom,lut-row-legend = <10000 9800 9600 9400 9200 9000>,
			<8800 8600 8400 8200 8000 7800>,
			<7600 7400 7200 7000 6800 6600>,
			<6400 6200 6000 5800 5600 5400>,
			<5200 5000 4800 4600 4400 4200>,
			<4000 3800 3600 3400 3200 3000>,
			<2800 2600 2400 2200 2000 1800>,
			<1600 1400 1200 1000 900 800>,
			<700 600 500 400 300 200>,
			<100 0>;
		qcom,lut-data = <6768 5755 5308 5069 5017 5006>,
			<6730 5763 5308 5068 5017 5005>,
			<6694 5765 5307 5068 5017 5005>,
			<6660 5765 5305 5068 5018 5005>,
			<6629 5762 5303 5068 5018 5005>,
			<6605 5757 5299 5069 5019 5006>,
			<6587 5749 5295 5070 5021 5007>,
			<6571 5737 5290 5072 5022 5008>,
			<6543 5728 5288 5073 5024 5010>,
			<6491 5719 5287 5076 5026 5011>,
			<6462 5716 5286 5079 5028 5013>,
			<6480 5724 5286 5082 5030 5015>,
			<6508 5737 5288 5086 5032 5017>,
			<6492 5737 5293 5091 5036 5019>,
			<6366 5730 5308 5098 5040 5022>,
			<6271 5718 5317 5104 5044 5025>,
			<6256 5684 5316 5108 5047 5028>,
			<6246 5642 5314 5113 5050 5031>,
			<6236 5629 5306 5120 5056 5036>,
			<6224 5625 5282 5131 5065 5043>,
			<6212 5621 5259 5137 5069 5045>,
			<6198 5607 5242 5115 5056 5037>,
			<6185 5591 5228 5082 5038 5023>,
			<6184 5587 5221 5069 5027 5015>,
			<6192 5585 5217 5062 5019 5008>,
			<6204 5585 5215 5060 5016 5005>,
			<6221 5583 5216 5061 5017 5006>,
			<6243 5579 5218 5063 5018 5007>,
			<6266 5583 5219 5065 5021 5008>,
			<6290 5608 5221 5069 5025 5011>,
			<6316 5636 5223 5073 5029 5014>,
			<6341 5661 5225 5077 5034 5018>,
			<6368 5689 5226 5081 5038 5022>,
			<6397 5719 5231 5084 5039 5025>,
			<6427 5751 5244 5087 5039 5027>,
			<6458 5785 5257 5088 5039 5027>,
			<6489 5821 5271 5087 5032 5019>,
			<6523 5861 5286 5085 5024 5010>,
			<6558 5904 5300 5083 5023 5009>,
			<6598 5954 5315 5082 5023 5009>,
			<6640 6005 5330 5081 5023 5010>,
			<6681 6058 5344 5084 5025 5011>,
			<6726 6114 5360 5086 5026 5011>,
			<6784 6174 5380 5086 5023 5008>,
			<6827 6246 5401 5086 5022 5007>,
			<6729 6214 5396 5088 5028 5014>,
			<6764 6275 5423 5097 5035 5020>,
			<6824 6344 5457 5107 5044 5032>,
			<6893 6426 5497 5121 5055 5041>,
			<6965 6518 5532 5126 5045 5029>,
			<7037 6594 5555 5113 5033 5017>,
			<7134 6702 5604 5115 5036 5020>,
			<7287 6847 5691 5132 5046 5027>,
			<7547 7010 5811 5165 5074 5056>,
			<7547 7010 5811 5165 5074 5056>,
			<7547 7010 5811 5165 5074 5056>;
	};

};
